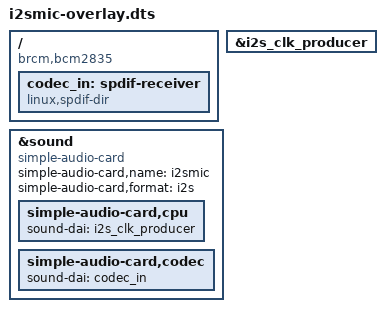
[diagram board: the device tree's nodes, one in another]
/dts-v1/;
/plugin/;

/ {
    compatible = "brcm,bcm2835";

    fragment@0 {
        target = <&i2s_clk_producer>;
        __overlay__ {
            #sound-dai-cells = <0>;
            status = "okay";
        };
    };

    fragment@1 {
        target-path = "/";
        __overlay__ {
            codec_in: spdif-receiver {
                #sound-dai-cells = <0>;
                compatible = "linux,spdif-dir";
                status = "okay";
            };
        };
    };

    fragment@2 {
        target = <&sound>;
        __overlay__ {
            compatible = "simple-audio-card";
            simple-audio-card,name = "i2smic";
            simple-audio-card,format = "i2s";
            status = "okay";

            simple-audio-card,cpu {
                sound-dai = <&i2s_clk_producer>;
            };
            simple-audio-card,codec {
                sound-dai = <&codec_in>;
            };
        };
    };
};
